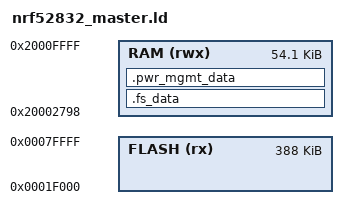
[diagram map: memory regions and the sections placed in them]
/* Linker script to configure memory regions. */

SEARCH_DIR(.)
GROUP(-lgcc -lc -lnosys)

MEMORY
{
  FLASH (rx) : ORIGIN = 0x1f000, LENGTH = 0x61000
  RAM (rwx) :  ORIGIN = 0x20002798, LENGTH = 0xd868
}

SECTIONS
{
  .fs_data :
  {
    PROVIDE(__start_fs_data = .);
    KEEP(*(.fs_data))
    PROVIDE(__stop_fs_data = .);
  } > RAM
  .pwr_mgmt_data :
  {
    PROVIDE(__start_pwr_mgmt_data = .);
    KEEP(*(.pwr_mgmt_data))
    PROVIDE(__stop_pwr_mgmt_data = .);
  } > RAM
} INSERT AFTER .data;

INCLUDE "nrf5x_common.ld"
